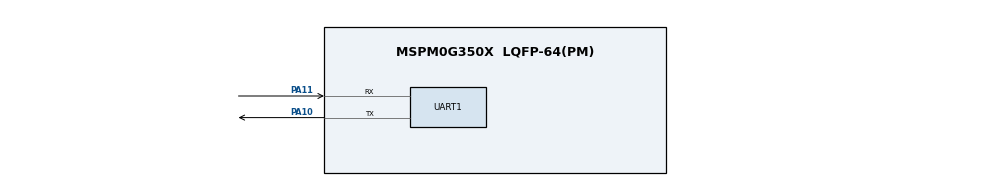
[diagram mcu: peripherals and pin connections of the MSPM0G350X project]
/**
 * @cliArgs --device "MSPM0G350X" --package "LQFP-64(PM)" --part "Default" --product "mspm0_sdk@2.01.00.03"
 * @versions {"tool":"1.20.0+3587"}
 */

/**
 * Import the modules used in this configuration.
 */
const GPIO   = scripting.addModule("/ti/driverlib/GPIO", {}, false);
const GPIO1  = GPIO.addInstance();
const GPIO2  = GPIO.addInstance();
const SYSCTL = scripting.addModule("/ti/driverlib/SYSCTL");
const UART   = scripting.addModule("/ti/driverlib/UART", {}, false);
const UART1  = UART.addInstance();

/**
 * Write custom configuration values to the imported modules.
 */
const divider7       = system.clockTree["PLL_PDIV"];
divider7.divideValue = 2;

const divider9       = system.clockTree["UDIV"];
divider9.divideValue = 2;

const multiplier2         = system.clockTree["PLL_QDIV"];
multiplier2.multiplyValue = 5;

const mux8       = system.clockTree["HSCLKMUX"];
mux8.inputSelect = "HSCLKMUX_SYSPLL2X";

GPIO1.$name                          = "GPIO_OLED";
GPIO1.associatedPins.create(2);
GPIO1.associatedPins[0].$name        = "PIN_SCL";
GPIO1.associatedPins[0].assignedPort = "PORTB";
GPIO1.associatedPins[0].assignedPin  = "3";
GPIO1.associatedPins[1].$name        = "PIN_SDA";
GPIO1.associatedPins[1].assignedPort = "PORTB";
GPIO1.associatedPins[1].assignedPin  = "2";

const Board = scripting.addModule("/ti/driverlib/Board", {}, false);

GPIO2.$name                              = "GPIO_Key";
GPIO2.associatedPins.create(4);
GPIO2.associatedPins[0].$name            = "GPIO_K3";
GPIO2.associatedPins[0].direction        = "INPUT";
GPIO2.associatedPins[0].assignedPort     = "PORTB";
GPIO2.associatedPins[0].assignedPin      = "9";
GPIO2.associatedPins[0].ioStructure      = "SD";
GPIO2.associatedPins[1].$name            = "GPIO_K4";
GPIO2.associatedPins[1].direction        = "INPUT";
GPIO2.associatedPins[1].internalResistor = "PULL_UP";
GPIO2.associatedPins[1].assignedPort     = "PORTA";
GPIO2.associatedPins[1].assignedPin      = "27";
GPIO2.associatedPins[1].ioStructure      = "SD";
GPIO2.associatedPins[2].$name            = "GPIO_K1";
GPIO2.associatedPins[2].direction        = "INPUT";
GPIO2.associatedPins[2].internalResistor = "PULL_UP";
GPIO2.associatedPins[2].assignedPort     = "PORTA";
GPIO2.associatedPins[2].assignedPin      = "26";
GPIO2.associatedPins[3].$name            = "GPIO_K2";
GPIO2.associatedPins[3].direction        = "INPUT";
GPIO2.associatedPins[3].assignedPort     = "PORTB";
GPIO2.associatedPins[3].internalResistor = "PULL_UP";
GPIO2.associatedPins[3].assignedPin      = "24";

SYSCTL.forceDefaultClkConfig = true;
SYSCTL.clockTreeEn           = true;

UART1.$name                    = "UART_0";
UART1.targetBaudRate           = 115200;
UART1.enabledInterrupts        = ["RX"];
UART1.enableFIFO               = true;
UART1.rxFifoThreshold          = "DL_UART_RX_FIFO_LEVEL_ONE_ENTRY";
UART1.txFifoThreshold          = "DL_UART_TX_FIFO_LEVEL_3_4_EMPTY";
UART1.peripheral.$assign       = "UART0";
UART1.peripheral.rxPin.$assign = "PA11";
UART1.peripheral.txPin.$assign = "PA10";
UART1.txPinConfig.$name        = "ti_driverlib_gpio_GPIOPinGeneric0";
UART1.rxPinConfig.$name        = "ti_driverlib_gpio_GPIOPinGeneric1";

/**
 * Pinmux solution for unlocked pins/peripherals. This ensures that minor changes to the automatic solver in a future
 * version of the tool will not impact the pinmux you originally saw.  These lines can be completely deleted in order to
 * re-solve from scratch.
 */
GPIO1.associatedPins[0].pin.$suggestSolution = "PB3";
GPIO1.associatedPins[1].pin.$suggestSolution = "PB2";
Board.peripheral.$suggestSolution            = "DEBUGSS";
Board.peripheral.swclkPin.$suggestSolution   = "PA20";
Board.peripheral.swdioPin.$suggestSolution   = "PA19";
GPIO2.associatedPins[0].pin.$suggestSolution = "PB9";
GPIO2.associatedPins[1].pin.$suggestSolution = "PA27";
GPIO2.associatedPins[2].pin.$suggestSolution = "PA26";
GPIO2.associatedPins[3].pin.$suggestSolution = "PB24";
